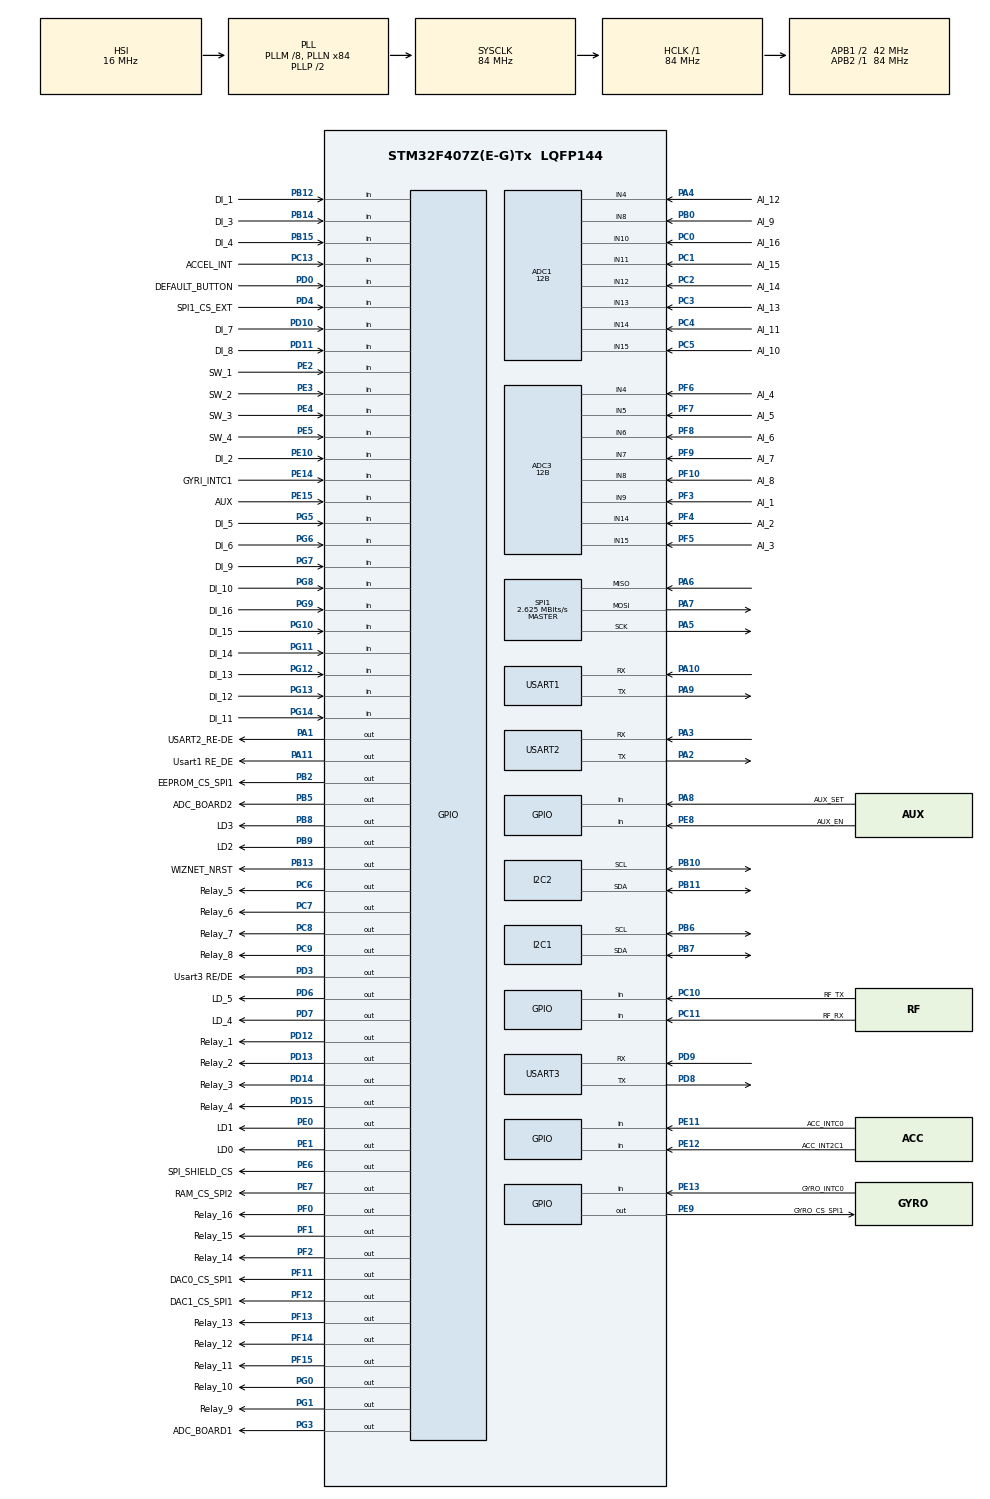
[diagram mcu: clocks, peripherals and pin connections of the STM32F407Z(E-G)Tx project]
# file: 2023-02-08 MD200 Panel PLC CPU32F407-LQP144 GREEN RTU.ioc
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ADC1.Channel-0\#ChannelRegularConversion=ADC_CHANNEL_4
ADC1.ClockPrescaler=ADC_CLOCK_SYNC_PCLK_DIV4
ADC1.InjNumberOfConversion=0
ADC1.NbrOfConversionFlag=1
ADC1.Rank-0\#ChannelRegularConversion=1
ADC1.Resolution=ADC_RESOLUTION_12B
ADC1.SamplingTime-0\#ChannelRegularConversion=ADC_SAMPLETIME_3CYCLES
ADC1.master=1
ADC3.Channel-0\#ChannelRegularConversion=ADC_CHANNEL_9
ADC3.EOCSelection=ADC_EOC_SINGLE_CONV
ADC3.NbrOfConversion=1
ADC3.NbrOfConversionFlag=1
ADC3.Rank-0\#ChannelRegularConversion=1
ADC3.Resolution=ADC_RESOLUTION_12B
ADC3.SamplingTime-0\#ChannelRegularConversion=ADC_SAMPLETIME_3CYCLES
Mcu.Family=STM32F4
Mcu.Name=STM32F407Z(E-G)Tx
Mcu.Package=LQFP144
NVIC.PriorityGroup=NVIC_PRIORITYGROUP_4
NVIC.TIM2_IRQn=true\:0\:0\:false\:false\:true\:true\:true\:true
NVIC.TIM7_IRQn=true\:0\:0\:false\:false\:true\:true\:true\:true
NVIC.TIM8_UP_TIM13_IRQn=true\:0\:0\:false\:false\:true\:true\:true\:true
NVIC.USART1_IRQn=true\:0\:0\:false\:false\:true\:true\:true\:true
NVIC.USART2_IRQn=true\:0\:0\:false\:false\:true\:true\:true\:true
NVIC.USART3_IRQn=true\:0\:0\:false\:false\:true\:true\:true\:true
PA1.GPIO_Label=USART2_RE-DE
PA1.Signal=GPIO_Output
PA10.Mode=Asynchronous
PA10.Signal=USART1_RX
PA11.GPIO_Label=Usart1 RE_DE
PA11.Signal=GPIO_Output
PA13.Mode=JTAG_5_pins
PA13.Signal=SYS_JTMS-SWDIO
PA14.Mode=JTAG_5_pins
PA14.Signal=SYS_JTCK-SWCLK
PA15.Mode=JTAG_5_pins
PA15.Signal=SYS_JTDI
PA2.Mode=Asynchronous
PA2.Signal=USART2_TX
PA3.Mode=Asynchronous
PA3.Signal=USART2_RX
PA4.GPIO_Label=AI_12
PA4.Signal=ADCx_IN4
PA5.Mode=Full_Duplex_Master
PA5.Signal=SPI1_SCK
PA6.Mode=Full_Duplex_Master
PA6.Signal=SPI1_MISO
PA7.Mode=Full_Duplex_Master
PA7.Signal=SPI1_MOSI
PA8.GPIO_Label=AUX_SET
PA8.Signal=GPIO_Input
PA9.Mode=Asynchronous
PA9.Signal=USART1_TX
PB0.GPIO_Label=AI_9
PB0.Signal=ADCx_IN8
PB10.Mode=I2C
PB10.Signal=I2C2_SCL
PB11.Mode=I2C
PB11.Signal=I2C2_SDA
PB12.GPIO_Label=DI_1
PB12.Signal=GPIO_Input
PB13.GPIO_Label=WIZNET_NRST
PB13.Signal=GPIO_Output
PB14.GPIO_Label=DI_3
PB14.Signal=GPIO_Input
PB15.GPIO_Label=DI_4
PB15.Signal=GPIO_Input
PB2.GPIO_Label=EEPROM_CS_SPI1
PB2.Signal=GPIO_Output
PB3.Mode=JTAG_5_pins
PB3.Signal=SYS_JTDO-SWO
PB4.Mode=JTAG_5_pins
PB4.Signal=SYS_JTRST
PB5.GPIO_Label=ADC_BOARD2
PB5.Signal=GPIO_Output
PB6.Mode=I2C
PB6.Signal=I2C1_SCL
PB7.Mode=I2C
PB7.Signal=I2C1_SDA
PB8.GPIO_Label=LD3
PB8.Signal=GPIO_Output
PB9.GPIO_Label=LD2
PB9.Signal=GPIO_Output
PC0.GPIO_Label=AI_16
PC0.Signal=ADCx_IN10
PC1.GPIO_Label=AI_15
PC1.Signal=ADCx_IN11
PC10.GPIO_Label=RF_TX
PC10.Signal=GPIO_Input
PC11.GPIO_Label=RF_RX
PC11.Signal=GPIO_Input
PC13-ANTI_TAMP.GPIO_Label=ACCEL_INT
PC13-ANTI_TAMP.Signal=GPIO_Input
PC14-OSC32_IN.Signal=RCC_OSC32_IN
PC15-OSC32_OUT.Signal=RCC_OSC32_OUT
PC2.GPIO_Label=AI_14
PC2.Signal=ADCx_IN12
PC3.GPIO_Label=AI_13
PC3.Signal=ADCx_IN13
PC4.GPIO_Label=AI_11
PC4.Signal=ADCx_IN14
PC5.GPIO_Label=AI_10
PC5.Signal=ADCx_IN15
PC6.GPIO_Label=Relay_5
PC6.Signal=GPIO_Output
PC7.GPIO_Label=Relay_6
PC7.Signal=GPIO_Output
PC8.GPIO_Label=Relay_7
PC8.Signal=GPIO_Output
PC9.GPIO_Label=Relay_8
PC9.Signal=GPIO_Output
PD0.GPIO_Label=DEFAULT_BUTTON
PD0.Signal=GPIO_Input
PD10.GPIO_Label=DI_7
PD10.Signal=GPIO_Input
PD11.GPIO_Label=DI_8
PD11.Signal=GPIO_Input
PD12.GPIO_Label=Relay_1
PD12.Signal=GPIO_Output
PD13.GPIO_Label=Relay_2
PD13.Signal=GPIO_Output
PD14.GPIO_Label=Relay_3
PD14.Signal=GPIO_Output
PD15.GPIO_Label=Relay_4
PD15.Signal=GPIO_Output
PD3.GPIO_Label=Usart3 RE/DE
PD3.Signal=GPIO_Output
PD4.GPIO_Label=SPI1_CS_EXT
PD4.Signal=GPIO_Input
PD6.GPIO_Label=LD_5
PD6.Signal=GPIO_Output
PD7.GPIO_Label=LD_4
PD7.Signal=GPIO_Output
PD8.Mode=Asynchronous
PD8.Signal=USART3_TX
PD9.Mode=Asynchronous
PD9.Signal=USART3_RX
PE0.GPIO_Label=LD1
PE0.Signal=GPIO_Output
PE1.GPIO_Label=LD0
PE1.Signal=GPIO_Output
PE10.GPIO_Label=DI_2
PE10.Signal=GPIO_Input
PE11.GPIO_Label=ACC_INTC0
PE11.Signal=GPIO_Input
PE12.GPIO_Label=ACC_INT2C1
PE12.Signal=GPIO_Input
PE13.GPIO_Label=GYRO_INTC0
PE13.Signal=GPIO_Input
PE14.GPIO_Label=GYRI_INTC1
PE14.Signal=GPIO_Input
PE15.GPIO_Label=AUX
PE15.Signal=GPIO_Input
PE2.GPIO_Label=SW_1
PE2.Signal=GPIO_Input
PE3.GPIO_Label=SW_2
PE3.Signal=GPIO_Input
PE4.GPIO_Label=SW_3
PE4.Signal=GPIO_Input
PE5.GPIO_Label=SW_4
PE5.Signal=GPIO_Input
PE6.GPIO_Label=SPI_SHIELD_CS
PE6.Signal=GPIO_Output
PE7.GPIO_Label=RAM_CS_SPI2
PE7.Signal=GPIO_Output
PE8.GPIO_Label=AUX_EN
PE8.Signal=GPIO_Input
PE9.GPIO_Label=GYRO_CS_SPI1
PE9.Signal=GPIO_Output
PF0.GPIO_Label=Relay_16
PF0.Signal=GPIO_Output
PF1.GPIO_Label=Relay_15
PF1.Signal=GPIO_Output
PF10.GPIO_Label=AI_8
PF10.Mode=IN8
PF10.Signal=ADC3_IN8
PF11.GPIO_Label=DAC0_CS_SPI1
PF11.Signal=GPIO_Output
PF12.GPIO_Label=DAC1_CS_SPI1
PF12.Signal=GPIO_Output
PF13.GPIO_Label=Relay_13
PF13.Signal=GPIO_Output
PF14.GPIO_Label=Relay_12
PF14.Signal=GPIO_Output
PF15.GPIO_Label=Relay_11
PF15.Signal=GPIO_Output
PF2.GPIO_Label=Relay_14
PF2.Signal=GPIO_Output
PF3.GPIO_Label=AI_1
PF3.Mode=IN9
PF3.Signal=ADC3_IN9
PF4.GPIO_Label=AI_2
PF4.Mode=IN14
PF4.Signal=ADC3_IN14
PF5.GPIO_Label=AI_3
PF5.Mode=IN15
PF5.Signal=ADC3_IN15
PF6.GPIO_Label=AI_4
PF6.Mode=IN4
PF6.Signal=ADC3_IN4
PF7.GPIO_Label=AI_5
PF7.Mode=IN5
PF7.Signal=ADC3_IN5
PF8.GPIO_Label=AI_6
PF8.Mode=IN6
PF8.Signal=ADC3_IN6
PF9.GPIO_Label=AI_7
PF9.Mode=IN7
PF9.Signal=ADC3_IN7
PG0.GPIO_Label=Relay_10
PG0.Signal=GPIO_Output
PG1.GPIO_Label=Relay_9
PG1.Signal=GPIO_Output
PG10.GPIO_Label=DI_15
PG10.Signal=GPIO_Input
PG11.GPIO_Label=DI_14
PG11.Signal=GPIO_Input
PG12.GPIO_Label=DI_13
PG12.Signal=GPIO_Input
PG13.GPIO_Label=DI_12
PG13.Signal=GPIO_Input
PG14.GPIO_Label=DI_11
PG14.Signal=GPIO_Input
PG3.GPIO_Label=ADC_BOARD1
PG3.Signal=GPIO_Output
PG5.GPIO_Label=DI_5
PG5.Signal=GPIO_Input
PG6.GPIO_Label=DI_6
PG6.Signal=GPIO_Input
PG7.GPIO_Label=DI_9
PG7.Signal=GPIO_Input
PG8.GPIO_Label=DI_10
PG8.Signal=GPIO_Input
PG9.GPIO_Label=DI_16
PG9.Signal=GPIO_Input
PH0-OSC_IN.Mode=HSE-External-Oscillator
PH0-OSC_IN.Signal=RCC_OSC_IN
PH1-OSC_OUT.Mode=HSE-External-Oscillator
PH1-OSC_OUT.Signal=RCC_OSC_OUT
ProjectManager.HeapSize=0x200
ProjectManager.StackSize=0x400
ProjectManager.TargetToolchain=STM32CubeIDE
RCC.48MHZClocksFreq_Value=42000000
RCC.AHBFreq_Value=84000000
RCC.APB1CLKDivider=RCC_HCLK_DIV2
RCC.APB1Freq_Value=42000000
RCC.APB1TimFreq_Value=84000000
RCC.APB2Freq_Value=84000000
RCC.APB2TimFreq_Value=84000000
RCC.CortexFreq_Value=84000000
RCC.HCLKFreq_Value=84000000
RCC.HSE_VALUE=24000000
RCC.HSI_VALUE=16000000
RCC.LSE_VALUE=32768
RCC.PLLM=8
RCC.PLLN=84
RCC.SYSCLKFreq_VALUE=84000000
RCC.SYSCLKSource=RCC_SYSCLKSOURCE_PLLCLK
RCC.VCOOutputFreq_Value=168000000
SH.ADCx_IN10.0=ADC1_IN10,IN10
SH.ADCx_IN11.0=ADC1_IN11,IN11
SH.ADCx_IN12.0=ADC1_IN12,IN12
SH.ADCx_IN13.0=ADC1_IN13,IN13
SH.ADCx_IN14.0=ADC1_IN14,IN14
SH.ADCx_IN15.0=ADC1_IN15,IN15
SH.ADCx_IN4.0=ADC1_IN4,IN4
SH.ADCx_IN8.0=ADC1_IN8,IN8
SPI1.BaudRatePrescaler=SPI_BAUDRATEPRESCALER_32
SPI1.CalculateBaudRate=2.625 MBits/s
SPI1.Direction=SPI_DIRECTION_2LINES
SPI1.Mode=SPI_MODE_MASTER
SPI1.VirtualType=VM_MASTER
TIM2.Period=8400000-1
TIM7.Period=8400-1
TIM7.Prescaler=100
TIM8.Period=8400-1
TIM8.Prescaler=10000
USART1.VirtualMode=VM_ASYNC
USART2.VirtualMode=VM_ASYNC
USART3.VirtualMode=VM_ASYNC
VP_TIM2_VS_ClockSourceINT.Mode=Internal
VP_TIM7_VS_ClockSourceINT.Mode=Enable_Timer
VP_TIM8_VS_ClockSourceINT.Mode=Internal
board=custom

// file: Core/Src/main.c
/* USER CODE BEGIN Header */
/**
  ******************************************************************************
  * @file           : main.c
  * @brief          : Main program body
  ******************************************************************************
  * @attention
  *
  * Copyright (c) 2022 STMicroelectronics.
  * All rights reserved.
  *
  * This software is licensed under terms that can be found in the LICENSE file
  * in the root directory of this software component.
  * If no LICENSE file comes with this software, it is provided AS-IS.
  *
  ******************************************************************************
  */
/* USER CODE END Header */
#include "main.h"
#include "WatchDog.h"

/* USER CODE BEGIN Includes */
#include "MicroPeripheral.h"
#include "PlcDefinition.h"
#include "Registers.h"
#include "DataTypeGsm.h"
#include "HoldingRegister.h"
#include "DataRegisterAssigment.h"
#include "DataSendProcess.h"
#include "Uarts.h"
#include "UartPortTimerProcess.h"
#include "Rtc.h"
#include "AnalogInput.h"
#include "DigitalInput.h"
#include "DigitalOutput.h"
#include "Modbus.h"
#include "TimerProcess.h"
#include "MC25LCxxx.h"
#include "Kalman.h"
#include "DefaultProcess.h"
#include "Initialize.h"
#include "Coils.h"
#include "Peripheral.h"
#include "PeripheralTest.h"
#include "SystemStates.h"
#include "ButtonProcess.h"
#include "HMI.h"

/* USER CODE END Includes */

ADC_HandleTypeDef hadc1;
ADC_HandleTypeDef hadc3;

I2C_HandleTypeDef hi2c1;
I2C_HandleTypeDef hi2c2;

SPI_HandleTypeDef hspi1;

TIM_HandleTypeDef htim2;
TIM_HandleTypeDef htim7;
TIM_HandleTypeDef htim8;

UART_HandleTypeDef huart1;
UART_HandleTypeDef huart2;
UART_HandleTypeDef huart3;

/* USER CODE BEGIN PV */

strcUART Uart[UART_COUNT];

#define BUFF_SIZE 800
uint8_t convEnd = 0;			//conv end flag

uint16_t adcBuff[BUFF_SIZE] = {0};		//to store converted values
uint16_t adcData[BUFF_SIZE] = {0};		//to use as a second buffer

strcREGISTERS Registers;

strcMASTERCODE MasterCode;

strcPLC Plc;

strcGSM GSM;

strcHMI HMI;

strcDATASENDCENTER DataSendCenter;

strcALERTES AlertES;

strcALERT Alerts;

strcCRITICALS Criticals;

strcAnalogInput AnalogInput;

strcSYSTEM System;

strcRTC RtcData;

strcRTCCounter RtcCounter;

strcADC ADC_Modules[MAX_AI_BOARD_COUNT];

strcKalman mKalmanFilter[AI_CHANNEL_COUNT];

unsigned char  HoldingRegister_Data[32768] ;

unsigned char  StatusRegister_Data[32768] ;

unsigned int InputRegister_Data[4];

unsigned int  CoilRegister_Data[COIL_INT_COUNT];

//
// Hex Data Array H
//
const unsigned char HexArray[16] = {'0','1','2','3','4','5','6','7','8','9','A','B','C','D','E','F'};
//
// InputParamaterList
//
unsigned char *InputParameterList[2];

static void MX_USART1_UART_Init_Custom(void);
void TankKg(void);

/* USER CODE END PV */

void SystemClock_Config(void);
static void MX_GPIO_Init(void);
static void MX_ADC1_Init(void);
static void MX_ADC3_Init(void);
static void MX_I2C1_Init(void);
static void MX_I2C2_Init(void);
static void MX_SPI1_Init(void);
static void MX_USART1_UART_Init(void);
static void MX_USART2_UART_Init(void);
static void MX_USART3_UART_Init(void);
static void MX_TIM2_Init(void);
static void MX_TIM7_Init(void);
static void MX_TIM8_Init(void);

/* USER CODE BEGIN 0 */
//
//void HAL_UART_RxCpltCallback(UART_HandleTypeDef *huart)
//{
//	unsigned short PortNo = 0;
//	unsigned char Data;
//	if(huart->Instance == USART1)
//		{
//			PortNo = 1;
//			Data = USART1->DR;
//		}
//	else
//		{
//			if(huart->Instance == USART2)
//				{
//					PortNo = 2;
//					Data = USART2->DR;
//				}
//			else
//				{
//					if(huart->Instance == USART3)
//									{
//										PortNo = 3;
//										Data = USART3->DR;
//									}
//				}
//
//		}
//
//	if(PortNo > 0 )
//		{
//			Uart[PortNo].PortDataEndCounter  = 0;
//
//			if(*Uart[PortNo].Offset >= *Uart[PortNo].BufferSize ) *Uart[PortNo].Offset  = 0;
//
//			Uart[PortNo].Data[*Uart[PortNo].Offset] =  Data;
//
//			*Uart[PortNo].Status = PORT_DATA_START;
//			*Uart[PortNo].Offset = *Uart[PortNo].Offset  + 1;
//		}
//}

void HAL_TIM_PeriodElapsedCallback(TIM_HandleTypeDef *htim)
 {
	 unsigned short Counter;
	 //
	 // Timers And Port Data End
	 //
	 if(htim->Instance==TIM2)
		 {
			  for(Counter= 0; Counter < TIMER_COUNT; Counter++)
				  {
					  if(Registers.Timers.Control[Counter]->Enable)
						  *Registers.Timers.Counter[Counter] = *Registers.Timers.Counter[Counter] + 1;
				  }

			  for(Counter= 0; Counter < UART_COUNT; Counter++)
				  {
					  if(*Uart[Counter].Status &  PORT_DATA_START)  *Uart[Counter].Status = *Uart[Counter].Status | PORT_DATA_STOP;
				  }
		 }

	 //
	 // Serial Port Data Process
	 //
	 if(htim->Instance==TIM7)
	 	 {
			  for (Counter=0; Counter < UART_COUNT; Counter++)
				  {
					if(*Uart[Counter].Status &  PORT_DATA_START)
						{
							Uart[Counter].PortDataEndCounter = Uart[Counter].PortDataEndCounter + 1;
							//*Uart[Counter].Status = *Uart[Counter].Status | PORT_DATA_STOP;
						}
				  }
	 	 }

//
	 if(htim->Instance==TIM8)
		 {
		 	 *RtcCounter.Master = *RtcCounter.Master + 1;
//		 	 if (Seconds[8]++ >= 10)
//		 	 {
//		 		 Seconds[8] = 0;
//		 		 if(Registers.Coil[0] & 0x80)
//		 		 	 {
//		 			 	 Registers.Coil[0] = Registers.Coil[0] & ~0x80;
//		 		 	 }
//		 		 else
//		 		 	 {
//						 Registers.Coil[0] = Registers.Coil[0] | 0x80;
//					 }
//		 	 }
		 }
}

// USART Error Handler
void HAL_UART_ErrorCallback(UART_HandleTypeDef *huart)
{
	//
	// Usart 1 Error
	//
	if(huart->Instance==USART1)
	  {

		  HAL_UART_DeInit(&huart1);
		  MX_USART1_UART_Init(); //my initialization code

		  SET_BIT(huart1.Instance->CR1, USART_CR1_PEIE | USART_CR1_RXNEIE);
	  }
	//
	// Usart 2 Error
	//
	if(huart->Instance==USART2)
	  {
		  HAL_UART_DeInit(&huart2);
		  MX_USART2_UART_Init(); //my initialization code

		  SET_BIT(huart2.Instance->CR1, USART_CR1_PEIE | USART_CR1_RXNEIE);
	  }
	//
	// Usart 3 Error
	//
	if(huart->Instance==USART3)
	  {

		  HAL_UART_DeInit(&huart3);
		  MX_USART3_UART_Init(); //my initialization code

		  SET_BIT(huart3.Instance->CR1, USART_CR1_PEIE | USART_CR1_RXNEIE);
	  }
}

void RelayTest(void)
{

	if(Registers.Coil[0] & 0x80)
		{
			Registers.Coil[0] = Registers.Coil[0] & ~0x80;
		}
	else
		{
			Registers.Coil[0] = Registers.Coil[0] | 0x80;
		}
}

void TankKg(void)
{
	unsigned short Counter ;
	float AmountKg;
	for(Counter = 0; Counter < 2; Counter++)
		{

			AmountKg = 0;
			if ( ( *System.Tanks.Capacity[Counter] > 0 ) && (*Plc.Peripheral.AnalogInput.Calculated[Counter] >0 ) )
				{
					AmountKg =  *System.Tanks.Capacity[Counter] * *Plc.Peripheral.AnalogInput.Calculated[Counter] / 100;
					AmountKg = AmountKg * *System.Tanks.Density[Counter];
				}

			*System.Tanks.AmoungKg[Counter] = AmountKg;
		}
}

void Peripherals(void)
{
	DigitalInput();

	DigitalOutput();

	AnalogInputs();
}

void PlcProcessStart(void)
{
	static unsigned char State = 0;
	if(Plc.Status->ProcessStart) return;

	switch(State)
		{
			case 0:
				TimerRestart(TIM_NO_PLC_PROCESS_START, *Plc.RunTime);
				State = 1;
				break;
			case 1:
				if (Registers.Timers.Control[TIM_NO_PLC_PROCESS_START]->Timeout)
					{
						Plc.Status->ProcessStart = 1;
						RelayEnable();
						TimerStop(TIM_NO_PLC_PROCESS_START);
					}
				break;
		}
}

static void MX_USART1_UART_Init_Custom(void)
{

  huart1.Instance = USART1;
  switch (*Plc.RTU.BaudRate)
	  {
		  case 0:
				  huart1.Init.BaudRate = 9600;
			  break;

		  case 1:
				  huart1.Init.BaudRate = 14400;
			  break;

		  case 2:
				  huart1.Init.BaudRate = 19200;
			  break;

		  case 3:
				  huart1.Init.BaudRate = 38400;
			  break;

		  case 4:
				  huart1.Init.BaudRate = 56000;
			  break;

		  case 5:
				  huart1.Init.BaudRate = 57600;
			  break;

		  case 6:
				  huart1.Init.BaudRate = 115200;
			  break;

  	  	  default:
  	  		  	  huart1.Init.BaudRate = 9600;
	  			break;

	  }

  switch (*Plc.RTU.DataBits)
	  {
  	  	  case 8:
  	  		  	  huart1.Init.WordLength = UART_WORDLENGTH_8B;
  	  			break;

  	  	  case 9:
	  		  	  huart1.Init.WordLength = UART_WORDLENGTH_9B;
	  			break;

  	  	  default:
	  		  	  huart1.Init.WordLength = UART_WORDLENGTH_8B;
	  			break;

	  }

  switch (*Plc.RTU.StopBits)
	  {
  	  	  case 1:
  	  		  	  huart1.Init.StopBits = UART_STOPBITS_1;
  	  			break;

  	  	  case 2:
  	  		  	  huart1.Init.StopBits = UART_STOPBITS_2;
	  			break;

  	  	  default:
	  		  	  huart1.Init.StopBits = UART_STOPBITS_1;
	  			break;

	  }

  switch (*Plc.RTU.Parity)
	  {
  	  	  case 0:
  	  		  	  huart1.Init.Parity = UART_PARITY_NONE;
  	  			break;

  	  	  case 1:
  	  		  	  huart1.Init.Parity = UART_PARITY_EVEN;
	  			break;

  	  	  case 2:
  	  		  	  huart1.Init.Parity = UART_PARITY_ODD;
	  			break;

  	  	  default:
  	  		huart1.Init.Parity = UART_PARITY_NONE;
	  			break;

	  }

  huart1.Init.Mode = UART_MODE_TX_RX;
  huart1.Init.HwFlowCtl = UART_HWCONTROL_NONE;
  huart1.Init.OverSampling = UART_OVERSAMPLING_16;
  if (HAL_UART_Init(&huart1) != HAL_OK)
  {
    Error_Handler();
  }
  /* USER CODE BEGIN USART1_Init 2 */

  /* USER CODE END USART1_Init 2 */

}

void HAL_GPIO_WRITE_ODR(GPIO_TypeDef* GPIOx, uint16_t GPIO_Pin)
{
  /* Check the parameters */
  assert_param(IS_GPIO_PIN(GPIO_Pin));

  GPIOx->ODR |= GPIO_Pin;
}

void HAL_I2C_ClearBusyFlagErrata(I2C_HandleTypeDef *hi2c) {

    static uint8_t resetTried = 0;
    if (resetTried == 1) {
        return ;
    }
    uint32_t SDA_PIN = GPIO_PIN_7;
    uint32_t SCL_PIN = GPIO_PIN_6;
    GPIO_InitTypeDef GPIO_InitStruct;

    // 1
    __HAL_I2C_DISABLE(hi2c);

    // 2
    GPIO_InitStruct.Pin = SDA_PIN|SCL_PIN;
    GPIO_InitStruct.Mode = GPIO_MODE_OUTPUT_OD;
    GPIO_InitStruct.Pull = GPIO_NOPULL;
    GPIO_InitStruct.Speed = GPIO_SPEED_FAST;
    HAL_GPIO_Init(GPIOB, &GPIO_InitStruct);

    HAL_GPIO_WRITE_ODR(GPIOB, SDA_PIN);
    HAL_GPIO_WRITE_ODR(GPIOB, SCL_PIN);

    // 3
    //GPIO_PinState pinState;
    if (HAL_GPIO_ReadPin(GPIOB, SDA_PIN) == GPIO_PIN_RESET) {
        for(;;){}
    }
    if (HAL_GPIO_ReadPin(GPIOB, SCL_PIN) == GPIO_PIN_RESET) {
        for(;;){}
    }

    // 4
    GPIO_InitStruct.Pin = SDA_PIN;
    HAL_GPIO_Init(GPIOB, &GPIO_InitStruct);

    HAL_GPIO_TogglePin(GPIOB, SDA_PIN);

    // 5
    if (HAL_GPIO_ReadPin(GPIOB, SDA_PIN) == GPIO_PIN_SET) {
        for(;;){}
    }

    // 6
    GPIO_InitStruct.Pin = SCL_PIN;
    HAL_GPIO_Init(GPIOB, &GPIO_InitStruct);

    HAL_GPIO_TogglePin(GPIOB, SCL_PIN);

    // 7
    if (HAL_GPIO_ReadPin(GPIOB, SCL_PIN) == GPIO_PIN_SET) {
        for(;;){}
    }

    // 8
    GPIO_InitStruct.Pin = SDA_PIN;
    HAL_GPIO_Init(GPIOB, &GPIO_InitStruct);

    HAL_GPIO_WRITE_ODR(GPIOB, SDA_PIN);

    // 9
    if (HAL_GPIO_ReadPin(GPIOB, SDA_PIN) == GPIO_PIN_RESET) {
        for(;;){}
    }

    // 10
    GPIO_InitStruct.Pin = SCL_PIN;
    HAL_GPIO_Init(GPIOB, &GPIO_InitStruct);

    HAL_GPIO_WRITE_ODR(GPIOB, SCL_PIN);

    // 11
    if (HAL_GPIO_ReadPin(GPIOB, SCL_PIN) == GPIO_PIN_RESET) {
        for(;;){}
    }

    // 12
//    GPIO_InitStruct.Pin = SDA_PIN|SCL_PIN;
//    GPIO_InitStruct.Mode = GPIO_MODE_AF_OD;
//    GPIO_InitStruct.Alternate = I2C ; //NUCLEO_I2C_EXPBD_SCL_SDA_AF;
//    HAL_GPIO_Init(GPIOB, &GPIO_InitStruct);

    GPIO_InitStruct.Pin = GPIO_PIN_6|GPIO_PIN_7;
    GPIO_InitStruct.Mode = GPIO_MODE_AF_OD;
    GPIO_InitStruct.Pull = GPIO_NOPULL;
    GPIO_InitStruct.Speed = GPIO_SPEED_FREQ_VERY_HIGH;
    GPIO_InitStruct.Alternate = GPIO_AF4_I2C1;
    HAL_GPIO_Init(GPIOB, &GPIO_InitStruct);

   // 13
   hi2c->Instance->CR1 |= I2C_CR1_SWRST;

   // 14
   hi2c->Instance->CR1 ^= I2C_CR1_SWRST;

   // 15
   __HAL_I2C_ENABLE(hi2c);

   resetTried = 1;
}
/* USER CODE END 0 */

int main(void)
{

  /* MCU Configuration--------------------------------------------------------*/

  /* Reset of all peripherals, Initializes the Flash interface and the Systick. */
  HAL_Init();

  /* Configure the system clock */
  SystemClock_Config();

  /* Initialize all configured peripherals */
  MX_GPIO_Init();
  MX_ADC1_Init();
  MX_ADC3_Init();
  MX_I2C1_Init();
  MX_I2C2_Init();
  MX_SPI1_Init();
  MX_USART1_UART_Init();
  MX_USART2_UART_Init();
  MX_USART3_UART_Init();
  MX_TIM2_Init();
  MX_TIM7_Init();
  MX_TIM8_Init();
  /* USER CODE BEGIN 2 */
  //
  	// Register Address Asignment
  	//
  	SetRegisterData();
  	//
  	Initialize();
  	//
  	//
  	//

  	//
  	// Test
  	//
  	PeripheralTest();
  	//
  	// EEPRom Initialize And Read
  	//
  	//
  	// EEProm Init
  	//
  	MC25LCxxx_Init(&hspi1);
  	//
  	// Read EEPROM
  	//
  	MC25LCxxx_Read(&hspi1, EEPROM_NO_00, Registers.Holding);
  	//
  	//
  	//

    HAL_UART_DeInit(&huart1);
    MX_USART1_UART_Init_Custom();

  	//
  	// Wathdog Initialize
  	//
  	//WatchDogInit();

  	// Default Process
  	//
  	DefaultProcess();
  	//
   	// Kalman İnitialize
   	//
   	InitKalmanParameter();
  	//
  	// Timer
  	//
   	HAL_TIM_Base_Start_IT(&htim2);

  	//HAL_TIM_Base_Start_IT(&htim5);

  	//HAL_TIM_Base_Start_IT(&htim6);

  	HAL_TIM_Base_Start_IT(&htim7);

  	HAL_TIM_Base_Start_IT(&htim8);

  	*Uart[1].DataEnd = 50;
  	*Uart[2].DataEnd = 50;
  	*Uart[3].DataEnd = 100;
  	*Uart[4].DataEnd = 20;

  	*System.State = SYSTEM_STATE_NONE;

  	Plc.Status->ProcessStart = 0;

  	UART3_ETHERNET_ENABLE;

  	UART1_RS485_TRANSMIT_ENABLE;

  	HAL_UART_Transmit(&huart1, (unsigned char *)"Uart 1 Test\r\n", 13, 100);

  	UART1_RS485_RECEIVE_ENABLE;

  	UART3_RS485_TRANSMIT_ENABLE;

  	HAL_UART_Transmit(&huart3, (unsigned char *)"Uart 3 Test\r\n", 13, 100);

  	UART3_RS485_RECEIVE_ENABLE;

  	UART2_RS485_TRANSMIT_ENABLE; UART2_RS485_RECEIVE_DISABLE;

  	HAL_ADC_MspInit(&hadc1);
  	HAL_ADC_MspInit(&hadc3);

  	//HAL_ADC_Start_IT(&hadc1);
  	//HAL_ADC_Start_IT(&hadc3);
  /* USER CODE END 2 */

  /* Infinite loop */
  while (1)
  {

    /* USER CODE BEGIN 3 */

	PlcProcessStart();

	Peripherals();

	HoldingRegisterWrite();

	UpdateHoldingRegister();

	CheckUsartPortDataEndTimeOut();

	ProtocolModbus();

	TimerControlProcess();

	RtcSecondUpdate();

	RtcAdjust();

	//SystemStateProcess();

	//TcpDataSend();

	SetRegisterDataDefault();

	TankKg();

	HMIData();

	ButtonProcess();

	WatchDogFeed();
  }
  /* USER CODE END 3 */
}

void SystemClock_Config(void)
{
  RCC_OscInitTypeDef RCC_OscInitStruct = {0};
  RCC_ClkInitTypeDef RCC_ClkInitStruct = {0};

  /** Configure the main internal regulator output voltage
  */
  __HAL_RCC_PWR_CLK_ENABLE();
  __HAL_PWR_VOLTAGESCALING_CONFIG(PWR_REGULATOR_VOLTAGE_SCALE1);

  /** Initializes the RCC Oscillators according to the specified parameters
  * in the RCC_OscInitTypeDef structure.
  */
  RCC_OscInitStruct.OscillatorType = RCC_OSCILLATORTYPE_HSI;
  RCC_OscInitStruct.HSIState = RCC_HSI_ON;
  RCC_OscInitStruct.HSICalibrationValue = RCC_HSICALIBRATION_DEFAULT;
  RCC_OscInitStruct.PLL.PLLState = RCC_PLL_ON;
  RCC_OscInitStruct.PLL.PLLSource = RCC_PLLSOURCE_HSI;
  RCC_OscInitStruct.PLL.PLLM = 8;
  RCC_OscInitStruct.PLL.PLLN = 84;
  RCC_OscInitStruct.PLL.PLLP = RCC_PLLP_DIV2;
  RCC_OscInitStruct.PLL.PLLQ = 4;
  if (HAL_RCC_OscConfig(&RCC_OscInitStruct) != HAL_OK)
  {
    Error_Handler();
  }

  /** Initializes the CPU, AHB and APB buses clocks
  */
  RCC_ClkInitStruct.ClockType = RCC_CLOCKTYPE_HCLK|RCC_CLOCKTYPE_SYSCLK
                              |RCC_CLOCKTYPE_PCLK1|RCC_CLOCKTYPE_PCLK2;
  RCC_ClkInitStruct.SYSCLKSource = RCC_SYSCLKSOURCE_PLLCLK;
  RCC_ClkInitStruct.AHBCLKDivider = RCC_SYSCLK_DIV1;
  RCC_ClkInitStruct.APB1CLKDivider = RCC_HCLK_DIV2;
  RCC_ClkInitStruct.APB2CLKDivider = RCC_HCLK_DIV1;

  if (HAL_RCC_ClockConfig(&RCC_ClkInitStruct, FLASH_LATENCY_2) != HAL_OK)
  {
    Error_Handler();
  }
}

static void MX_ADC1_Init(void)
{

  ADC_ChannelConfTypeDef sConfig = {0};

  /** Configure the global features of the ADC (Clock, Resolution, Data Alignment and number of conversion)
  */
  hadc1.Instance = ADC1;
  hadc1.Init.ClockPrescaler = ADC_CLOCK_SYNC_PCLK_DIV4;
  hadc1.Init.Resolution = ADC_RESOLUTION_12B;
  hadc1.Init.ScanConvMode = DISABLE;
  hadc1.Init.ContinuousConvMode = DISABLE;
  hadc1.Init.DiscontinuousConvMode = DISABLE;
  hadc1.Init.ExternalTrigConvEdge = ADC_EXTERNALTRIGCONVEDGE_NONE;
  hadc1.Init.ExternalTrigConv = ADC_SOFTWARE_START;
  hadc1.Init.DataAlign = ADC_DATAALIGN_RIGHT;
  hadc1.Init.NbrOfConversion = 1;
  hadc1.Init.DMAContinuousRequests = DISABLE;
  hadc1.Init.EOCSelection = ADC_EOC_SINGLE_CONV;
  if (HAL_ADC_Init(&hadc1) != HAL_OK)
  {
    Error_Handler();
  }

  /** Configure for the selected ADC regular channel its corresponding rank in the sequencer and its sample time.
  */
  sConfig.Channel = ADC_CHANNEL_4;
  sConfig.Rank = 1;
  sConfig.SamplingTime = ADC_SAMPLETIME_3CYCLES;
  if (HAL_ADC_ConfigChannel(&hadc1, &sConfig) != HAL_OK)
  {
    Error_Handler();
  }

}

static void MX_ADC3_Init(void)
{

  ADC_ChannelConfTypeDef sConfig = {0};

  /** Configure the global features of the ADC (Clock, Resolution, Data Alignment and number of conversion)
  */
  hadc3.Instance = ADC3;
  hadc3.Init.ClockPrescaler = ADC_CLOCK_SYNC_PCLK_DIV4;
  hadc3.Init.Resolution = ADC_RESOLUTION_12B;
  hadc3.Init.ScanConvMode = DISABLE;
  hadc3.Init.ContinuousConvMode = DISABLE;
  hadc3.Init.DiscontinuousConvMode = DISABLE;
  hadc3.Init.ExternalTrigConvEdge = ADC_EXTERNALTRIGCONVEDGE_NONE;
  hadc3.Init.ExternalTrigConv = ADC_SOFTWARE_START;
  hadc3.Init.DataAlign = ADC_DATAALIGN_RIGHT;
  hadc3.Init.NbrOfConversion = 1;
  hadc3.Init.DMAContinuousRequests = DISABLE;
  hadc3.Init.EOCSelection = ADC_EOC_SINGLE_CONV;
  if (HAL_ADC_Init(&hadc3) != HAL_OK)
  {
    Error_Handler();
  }

  /** Configure for the selected ADC regular channel its corresponding rank in the sequencer and its sample time.
  */
  sConfig.Channel = ADC_CHANNEL_9;
  sConfig.Rank = 1;
  sConfig.SamplingTime = ADC_SAMPLETIME_3CYCLES;
  if (HAL_ADC_ConfigChannel(&hadc3, &sConfig) != HAL_OK)
  {
    Error_Handler();
  }

}

static void MX_I2C1_Init(void)
{

  hi2c1.Instance = I2C1;
  hi2c1.Init.ClockSpeed = 100000;
  hi2c1.Init.DutyCycle = I2C_DUTYCYCLE_2;
  hi2c1.Init.OwnAddress1 = 0;
  hi2c1.Init.AddressingMode = I2C_ADDRESSINGMODE_7BIT;
  hi2c1.Init.DualAddressMode = I2C_DUALADDRESS_DISABLE;
  hi2c1.Init.OwnAddress2 = 0;
  hi2c1.Init.GeneralCallMode = I2C_GENERALCALL_DISABLE;
  hi2c1.Init.NoStretchMode = I2C_NOSTRETCH_DISABLE;
  if (HAL_I2C_Init(&hi2c1) != HAL_OK)
  {
    Error_Handler();
  }

}

static void MX_I2C2_Init(void)
{

  hi2c2.Instance = I2C2;
  hi2c2.Init.ClockSpeed = 100000;
  hi2c2.Init.DutyCycle = I2C_DUTYCYCLE_2;
  hi2c2.Init.OwnAddress1 = 0;
  hi2c2.Init.AddressingMode = I2C_ADDRESSINGMODE_7BIT;
  hi2c2.Init.DualAddressMode = I2C_DUALADDRESS_DISABLE;
  hi2c2.Init.OwnAddress2 = 0;
  hi2c2.Init.GeneralCallMode = I2C_GENERALCALL_DISABLE;
  hi2c2.Init.NoStretchMode = I2C_NOSTRETCH_DISABLE;
  if (HAL_I2C_Init(&hi2c2) != HAL_OK)
  {
    Error_Handler();
  }

}

static void MX_SPI1_Init(void)
{

  /* SPI1 parameter configuration*/
  hspi1.Instance = SPI1;
  hspi1.Init.Mode = SPI_MODE_MASTER;
  hspi1.Init.Direction = SPI_DIRECTION_2LINES;
  hspi1.Init.DataSize = SPI_DATASIZE_8BIT;
  hspi1.Init.CLKPolarity = SPI_POLARITY_LOW;
  hspi1.Init.CLKPhase = SPI_PHASE_1EDGE;
  hspi1.Init.NSS = SPI_NSS_SOFT;
  hspi1.Init.BaudRatePrescaler = SPI_BAUDRATEPRESCALER_32;
  hspi1.Init.FirstBit = SPI_FIRSTBIT_MSB;
  hspi1.Init.TIMode = SPI_TIMODE_DISABLE;
  hspi1.Init.CRCCalculation = SPI_CRCCALCULATION_DISABLE;
  hspi1.Init.CRCPolynomial = 10;
  if (HAL_SPI_Init(&hspi1) != HAL_OK)
  {
    Error_Handler();
  }

}

static void MX_TIM2_Init(void)
{

  TIM_ClockConfigTypeDef sClockSourceConfig = {0};
  TIM_MasterConfigTypeDef sMasterConfig = {0};

  htim2.Instance = TIM2;
  htim2.Init.Prescaler = 0;
  htim2.Init.CounterMode = TIM_COUNTERMODE_UP;
  htim2.Init.Period = 8400000-1;
  htim2.Init.ClockDivision = TIM_CLOCKDIVISION_DIV1;
  htim2.Init.AutoReloadPreload = TIM_AUTORELOAD_PRELOAD_DISABLE;
  if (HAL_TIM_Base_Init(&htim2) != HAL_OK)
  {
    Error_Handler();
  }
  sClockSourceConfig.ClockSource = TIM_CLOCKSOURCE_INTERNAL;
  if (HAL_TIM_ConfigClockSource(&htim2, &sClockSourceConfig) != HAL_OK)
  {
    Error_Handler();
  }
  sMasterConfig.MasterOutputTrigger = TIM_TRGO_RESET;
  sMasterConfig.MasterSlaveMode = TIM_MASTERSLAVEMODE_DISABLE;
  if (HAL_TIMEx_MasterConfigSynchronization(&htim2, &sMasterConfig) != HAL_OK)
  {
    Error_Handler();
  }

}

static void MX_TIM7_Init(void)
{

  TIM_MasterConfigTypeDef sMasterConfig = {0};

  htim7.Instance = TIM7;
  htim7.Init.Prescaler = 100;
  htim7.Init.CounterMode = TIM_COUNTERMODE_UP;
  htim7.Init.Period = 8400-1;
  htim7.Init.AutoReloadPreload = TIM_AUTORELOAD_PRELOAD_DISABLE;
  if (HAL_TIM_Base_Init(&htim7) != HAL_OK)
  {
    Error_Handler();
  }
  sMasterConfig.MasterOutputTrigger = TIM_TRGO_RESET;
  sMasterConfig.MasterSlaveMode = TIM_MASTERSLAVEMODE_DISABLE;
  if (HAL_TIMEx_MasterConfigSynchronization(&htim7, &sMasterConfig) != HAL_OK)
  {
    Error_Handler();
  }

}

static void MX_TIM8_Init(void)
{

  TIM_ClockConfigTypeDef sClockSourceConfig = {0};
  TIM_MasterConfigTypeDef sMasterConfig = {0};

  htim8.Instance = TIM8;
  htim8.Init.Prescaler = 10000;
  htim8.Init.CounterMode = TIM_COUNTERMODE_UP;
  htim8.Init.Period = 8400-1;
  htim8.Init.ClockDivision = TIM_CLOCKDIVISION_DIV1;
  htim8.Init.RepetitionCounter = 0;
  htim8.Init.AutoReloadPreload = TIM_AUTORELOAD_PRELOAD_DISABLE;
  if (HAL_TIM_Base_Init(&htim8) != HAL_OK)
  {
    Error_Handler();
  }
  sClockSourceConfig.ClockSource = TIM_CLOCKSOURCE_INTERNAL;
  if (HAL_TIM_ConfigClockSource(&htim8, &sClockSourceConfig) != HAL_OK)
  {
    Error_Handler();
  }
  sMasterConfig.MasterOutputTrigger = TIM_TRGO_RESET;
  sMasterConfig.MasterSlaveMode = TIM_MASTERSLAVEMODE_DISABLE;
  if (HAL_TIMEx_MasterConfigSynchronization(&htim8, &sMasterConfig) != HAL_OK)
  {
    Error_Handler();
  }

}

static void MX_USART1_UART_Init(void)
{

  huart1.Instance = USART1;
  huart1.Init.BaudRate = 115200;
  huart1.Init.WordLength = UART_WORDLENGTH_8B;
  huart1.Init.StopBits = UART_STOPBITS_1;
  huart1.Init.Parity = UART_PARITY_NONE;
  huart1.Init.Mode = UART_MODE_TX_RX;
  huart1.Init.HwFlowCtl = UART_HWCONTROL_NONE;
  huart1.Init.OverSampling = UART_OVERSAMPLING_16;
  if (HAL_UART_Init(&huart1) != HAL_OK)
  {
    Error_Handler();
  }

}

static void MX_USART2_UART_Init(void)
{

  huart2.Instance = USART2;
  huart2.Init.BaudRate = 115200;
  huart2.Init.WordLength = UART_WORDLENGTH_8B;
  huart2.Init.StopBits = UART_STOPBITS_1;
  huart2.Init.Parity = UART_PARITY_NONE;
  huart2.Init.Mode = UART_MODE_TX_RX;
  huart2.Init.HwFlowCtl = UART_HWCONTROL_NONE;
  huart2.Init.OverSampling = UART_OVERSAMPLING_16;
  if (HAL_UART_Init(&huart2) != HAL_OK)
  {
    Error_Handler();
  }

}

static void MX_USART3_UART_Init(void)
{

  huart3.Instance = USART3;
  huart3.Init.BaudRate = 115200;
  huart3.Init.WordLength = UART_WORDLENGTH_8B;
  huart3.Init.StopBits = UART_STOPBITS_1;
  huart3.Init.Parity = UART_PARITY_NONE;
  huart3.Init.Mode = UART_MODE_TX_RX;
  huart3.Init.HwFlowCtl = UART_HWCONTROL_NONE;
  huart3.Init.OverSampling = UART_OVERSAMPLING_16;
  if (HAL_UART_Init(&huart3) != HAL_OK)
  {
    Error_Handler();
  }

}

static void MX_GPIO_Init(void)
{
  GPIO_InitTypeDef GPIO_InitStruct = {0};

  /* GPIO Ports Clock Enable */
  __HAL_RCC_GPIOE_CLK_ENABLE();
  __HAL_RCC_GPIOC_CLK_ENABLE();
  __HAL_RCC_GPIOF_CLK_ENABLE();
  __HAL_RCC_GPIOH_CLK_ENABLE();
  __HAL_RCC_GPIOA_CLK_ENABLE();
  __HAL_RCC_GPIOB_CLK_ENABLE();
  __HAL_RCC_GPIOG_CLK_ENABLE();
  __HAL_RCC_GPIOD_CLK_ENABLE();

  /*Configure GPIO pin Output Level */
  HAL_GPIO_WritePin(GPIOE, SPI_SHIELD_CS_Pin|RAM_CS_SPI2_Pin|GYRO_CS_SPI1_Pin|LD1_Pin
                          |LD0_Pin, GPIO_PIN_RESET);

  /*Configure GPIO pin Output Level */
  HAL_GPIO_WritePin(GPIOF, Relay_16_Pin|Relay_15_Pin|Relay_14_Pin|DAC0_CS_SPI1_Pin
                          |DAC1_CS_SPI1_Pin|Relay_13_Pin|Relay_12_Pin|Relay_11_Pin, GPIO_PIN_RESET);

  /*Configure GPIO pin Output Level */
  HAL_GPIO_WritePin(GPIOA, USART2_RE_DE_Pin|Usart1_RE_DE_Pin, GPIO_PIN_RESET);

  /*Configure GPIO pin Output Level */
  HAL_GPIO_WritePin(GPIOB, EEPROM_CS_SPI1_Pin|WIZNET_NRST_Pin|ADC_BOARD2_Pin|LD3_Pin
                          |LD2_Pin, GPIO_PIN_RESET);

  /*Configure GPIO pin Output Level */
  HAL_GPIO_WritePin(GPIOG, Relay_10_Pin|Relay_9_Pin|ADC_BOARD1_Pin, GPIO_PIN_RESET);

  /*Configure GPIO pin Output Level */
  HAL_GPIO_WritePin(GPIOD, Relay_1_Pin|Relay_2_Pin|Relay_3_Pin|Relay_4_Pin
                          |Usart3_RE_DE_Pin|LD_5_Pin|LD_4_Pin, GPIO_PIN_RESET);

  /*Configure GPIO pin Output Level */
  HAL_GPIO_WritePin(GPIOC, Relay_5_Pin|Relay_6_Pin|Relay_7_Pin|Relay_8_Pin, GPIO_PIN_RESET);

  /*Configure GPIO pins : SW_1_Pin SW_2_Pin SW_3_Pin SW_4_Pin
                           AUX_EN_Pin DI_2_Pin ACC_INTC0_Pin ACC_INT2C1_Pin
                           GYRO_INTC0_Pin GYRI_INTC1_Pin AUX_Pin */
  GPIO_InitStruct.Pin = SW_1_Pin|SW_2_Pin|SW_3_Pin|SW_4_Pin
                          |AUX_EN_Pin|DI_2_Pin|ACC_INTC0_Pin|ACC_INT2C1_Pin
                          |GYRO_INTC0_Pin|GYRI_INTC1_Pin|AUX_Pin;
  GPIO_InitStruct.Mode = GPIO_MODE_INPUT;
  GPIO_InitStruct.Pull = GPIO_NOPULL;
  HAL_GPIO_Init(GPIOE, &GPIO_InitStruct);

  /*Configure GPIO pins : SPI_SHIELD_CS_Pin RAM_CS_SPI2_Pin GYRO_CS_SPI1_Pin LD1_Pin
                           LD0_Pin */
  GPIO_InitStruct.Pin = SPI_SHIELD_CS_Pin|RAM_CS_SPI2_Pin|GYRO_CS_SPI1_Pin|LD1_Pin
                          |LD0_Pin;
  GPIO_InitStruct.Mode = GPIO_MODE_OUTPUT_PP;
  GPIO_InitStruct.Pull = GPIO_NOPULL;
  GPIO_InitStruct.Speed = GPIO_SPEED_FREQ_LOW;
  HAL_GPIO_Init(GPIOE, &GPIO_InitStruct);

  /*Configure GPIO pins : ACCEL_INT_Pin RF_TX_Pin RF_RX_Pin */
  GPIO_InitStruct.Pin = ACCEL_INT_Pin|RF_TX_Pin|RF_RX_Pin;
  GPIO_InitStruct.Mode = GPIO_MODE_INPUT;
  GPIO_InitStruct.Pull = GPIO_NOPULL;
  HAL_GPIO_Init(GPIOC, &GPIO_InitStruct);

  /*Configure GPIO pins : Relay_16_Pin Relay_15_Pin Relay_14_Pin DAC0_CS_SPI1_Pin
                           DAC1_CS_SPI1_Pin Relay_13_Pin Relay_12_Pin Relay_11_Pin */
  GPIO_InitStruct.Pin = Relay_16_Pin|Relay_15_Pin|Relay_14_Pin|DAC0_CS_SPI1_Pin
                          |DAC1_CS_SPI1_Pin|Relay_13_Pin|Relay_12_Pin|Relay_11_Pin;
  GPIO_InitStruct.Mode = GPIO_MODE_OUTPUT_PP;
  GPIO_InitStruct.Pull = GPIO_NOPULL;
  GPIO_InitStruct.Speed = GPIO_SPEED_FREQ_LOW;
  HAL_GPIO_Init(GPIOF, &GPIO_InitStruct);

  /*Configure GPIO pins : USART2_RE_DE_Pin Usart1_RE_DE_Pin */
  GPIO_InitStruct.Pin = USART2_RE_DE_Pin|Usart1_RE_DE_Pin;
  GPIO_InitStruct.Mode = GPIO_MODE_OUTPUT_PP;
  GPIO_InitStruct.Pull = GPIO_NOPULL;
  GPIO_InitStruct.Speed = GPIO_SPEED_FREQ_LOW;
  HAL_GPIO_Init(GPIOA, &GPIO_InitStruct);

  /*Configure GPIO pins : EEPROM_CS_SPI1_Pin WIZNET_NRST_Pin ADC_BOARD2_Pin LD3_Pin
                           LD2_Pin */
  GPIO_InitStruct.Pin = EEPROM_CS_SPI1_Pin|WIZNET_NRST_Pin|ADC_BOARD2_Pin|LD3_Pin
                          |LD2_Pin;
  GPIO_InitStruct.Mode = GPIO_MODE_OUTPUT_PP;
  GPIO_InitStruct.Pull = GPIO_NOPULL;
  GPIO_InitStruct.Speed = GPIO_SPEED_FREQ_LOW;
  HAL_GPIO_Init(GPIOB, &GPIO_InitStruct);

  /*Configure GPIO pins : Relay_10_Pin Relay_9_Pin ADC_BOARD1_Pin */
  GPIO_InitStruct.Pin = Relay_10_Pin|Relay_9_Pin|ADC_BOARD1_Pin;
  GPIO_InitStruct.Mode = GPIO_MODE_OUTPUT_PP;
  GPIO_InitStruct.Pull = GPIO_NOPULL;
  GPIO_InitStruct.Speed = GPIO_SPEED_FREQ_LOW;
  HAL_GPIO_Init(GPIOG, &GPIO_InitStruct);

  /*Configure GPIO pins : DI_1_Pin DI_3_Pin DI_4_Pin */
  GPIO_InitStruct.Pin = DI_1_Pin|DI_3_Pin|DI_4_Pin;
  GPIO_InitStruct.Mode = GPIO_MODE_INPUT;
  GPIO_InitStruct.Pull = GPIO_NOPULL;
  HAL_GPIO_Init(GPIOB, &GPIO_InitStruct);

  /*Configure GPIO pins : DI_7_Pin DI_8_Pin DEFAULT_BUTTON_Pin SPI1_CS_EXT_Pin */
  GPIO_InitStruct.Pin = DI_7_Pin|DI_8_Pin|DEFAULT_BUTTON_Pin|SPI1_CS_EXT_Pin;
  GPIO_InitStruct.Mode = GPIO_MODE_INPUT;
  GPIO_InitStruct.Pull = GPIO_NOPULL;
  HAL_GPIO_Init(GPIOD, &GPIO_InitStruct);

  /*Configure GPIO pins : Relay_1_Pin Relay_2_Pin Relay_3_Pin Relay_4_Pin
                           Usart3_RE_DE_Pin LD_5_Pin LD_4_Pin */
  GPIO_InitStruct.Pin = Relay_1_Pin|Relay_2_Pin|Relay_3_Pin|Relay_4_Pin
                          |Usart3_RE_DE_Pin|LD_5_Pin|LD_4_Pin;
  GPIO_InitStruct.Mode = GPIO_MODE_OUTPUT_PP;
  GPIO_InitStruct.Pull = GPIO_NOPULL;
  GPIO_InitStruct.Speed = GPIO_SPEED_FREQ_LOW;
  HAL_GPIO_Init(GPIOD, &GPIO_InitStruct);

  /*Configure GPIO pins : DI_5_Pin DI_6_Pin DI_9_Pin DI_10_Pin
                           DI_16_Pin DI_15_Pin DI_14_Pin DI_13_Pin
                           DI_12_Pin DI_11_Pin */
  GPIO_InitStruct.Pin = DI_5_Pin|DI_6_Pin|DI_9_Pin|DI_10_Pin
                          |DI_16_Pin|DI_15_Pin|DI_14_Pin|DI_13_Pin
                          |DI_12_Pin|DI_11_Pin;
  GPIO_InitStruct.Mode = GPIO_MODE_INPUT;
  GPIO_InitStruct.Pull = GPIO_NOPULL;
  HAL_GPIO_Init(GPIOG, &GPIO_InitStruct);

  /*Configure GPIO pins : Relay_5_Pin Relay_6_Pin Relay_7_Pin Relay_8_Pin */
  GPIO_InitStruct.Pin = Relay_5_Pin|Relay_6_Pin|Relay_7_Pin|Relay_8_Pin;
  GPIO_InitStruct.Mode = GPIO_MODE_OUTPUT_PP;
  GPIO_InitStruct.Pull = GPIO_NOPULL;
  GPIO_InitStruct.Speed = GPIO_SPEED_FREQ_LOW;
  HAL_GPIO_Init(GPIOC, &GPIO_InitStruct);

  /*Configure GPIO pin : AUX_SET_Pin */
  GPIO_InitStruct.Pin = AUX_SET_Pin;
  GPIO_InitStruct.Mode = GPIO_MODE_INPUT;
  GPIO_InitStruct.Pull = GPIO_NOPULL;
  HAL_GPIO_Init(AUX_SET_GPIO_Port, &GPIO_InitStruct);

}

void Error_Handler(void)
{
  __disable_irq();
  while (1)
  {
  }
}
